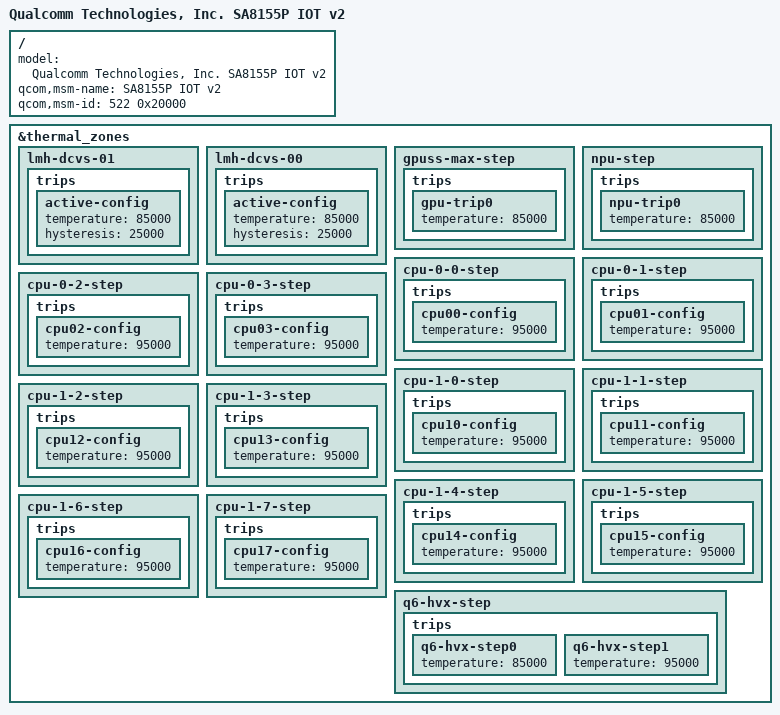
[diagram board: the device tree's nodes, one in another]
/* Copyright (c) 2018, 2021, The Linux Foundation. All rights reserved.
 *
 * This program is free software; you can redistribute it and/or modify
 * it under the terms of the GNU General Public License version 2 and
 * only version 2 as published by the Free Software Foundation.
 *
 * This program is distributed in the hope that it will be useful,
 * but WITHOUT ANY WARRANTY; without even the implied warranty of
 * MERCHANTABILITY or FITNESS FOR A PARTICULAR PURPOSE.  See the
 * GNU General Public License for more details.
 */

#include "sa8155-v2.dtsi"

/ {
	model = "Qualcomm Technologies, Inc. SA8155P IOT v2";
	qcom,msm-name = "SA8155P IOT v2";
	qcom,msm-id = <522 0x20000>;
};

&thermal_zones {
	lmh-dcvs-01 {
		trips {
			active-config {
				temperature = <85000>;
				hysteresis = <25000>;
			};
		};
	};

	lmh-dcvs-00 {
		trips {
			active-config {
				temperature = <85000>;
				hysteresis = <25000>;
			};
		};
	};

	gpuss-max-step {
		trips {
			gpu-trip0 {
				temperature = <85000>;
			};
		};
	};

	npu-step {
		trips {
			npu-trip0 {
				temperature = <85000>;
			};
		};
	};

	cpu-0-0-step {
		trips {
			cpu00-config {
				temperature = <95000>;
			};
		};
	};

	cpu-0-1-step {
		trips {
			cpu01-config {
				temperature = <95000>;
			};
		};
	};

	cpu-0-2-step {
		trips {
			cpu02-config {
				temperature = <95000>;
			};
		};
	};

	cpu-0-3-step {
		trips {
			cpu03-config {
				temperature = <95000>;
			};
		};
	};

	cpu-1-0-step {
		trips {
			cpu10-config {
				temperature = <95000>;
			};
		};
	};

	cpu-1-1-step {
		trips {
			cpu11-config {
				temperature = <95000>;
			};
		};
	};

	cpu-1-2-step {
		trips {
			cpu12-config {
				temperature = <95000>;
			};
		};
	};

	cpu-1-3-step {
		trips {
			cpu13-config {
				temperature = <95000>;
			};
		};
	};

	cpu-1-4-step {
		trips {
			cpu14-config {
				temperature = <95000>;
			};
		};
	};

	cpu-1-5-step {
		trips {
			cpu15-config {
				temperature = <95000>;
			};
		};
	};

	cpu-1-6-step {
		trips {
			cpu16-config {
				temperature = <95000>;
			};
		};
	};

	cpu-1-7-step {
		trips {
			cpu17-config {
				temperature = <95000>;
			};
		};
	};

	q6-hvx-step {
		trips {
			q6-hvx-step0 {
				temperature = <85000>;
			};

			q6-hvx-step1 {
				temperature = <95000>;
			};
		};
	};
};
